# psoc6a2m register map
Vendor: Cypress Semiconductor; Series: psoc6a2m; File version: 1.0
CPU: CM4 r0p1, little endian, MPU, FPU, VTOR, 3 interrupt priority bits
Registers are 32-bit, read-write, reset 0x0 unless marked. A register's access mark holds for its fields unless they carry their own. Offsets are from the block's base; [hi:lo] are bit positions; 'fields as' and 'values as' point back to an identical list; <NAME> marks a mode.

## CSD0 — Capsense Controller
Base 0x40360000
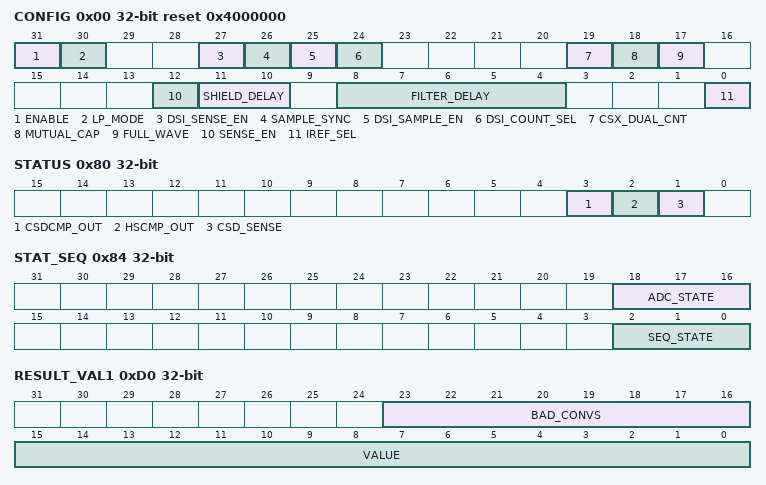
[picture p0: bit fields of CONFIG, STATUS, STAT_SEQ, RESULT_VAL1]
0x00 CONFIG reset 0x4000000 — Configuration and Control
  [31] ENABLE
  [30] LP_MODE
  [27] DSI_SENSE_EN — DSI_SENSE_EN = 1-> sensor clock is driven directly by DSI DSI_SENSE_EN = 0-> sensor clock is driven by PRS/divide-by-2/DIRECT_CLOCK
  [26] SAMPLE_SYNC
  [25] DSI_SAMPLE_EN — DSI_SAMPLE_EN = 1 -> COUNTER will count the samples generated by DSI DSI_SAMPLE_EN = 0 -> COUNTER will count the samples generated by CSD modulator
  [24] DSI_COUNT_SEL
    0=CSD_RESULT (N/A); 1=ADC_RESULT (N/A)
  [19] CSX_DUAL_CNT
    0=ONE (N/A); 1=TWO (N/A)
  [18] MUTUAL_CAP
    0=SELFCAP (Self-cap mode); 1=MUTUALCAP (Mutual-cap mode)
  [17] FULL_WAVE
    0=HALFWAVE (Half Wave mode); 1=FULLWAVE (Full Wave mode)
  [12] SENSE_EN — Enables the sensor and shield clocks, CSD modulator output and turns on the IDAC compensation current as selected by CSD_IDAC.
  [11:10] SHIELD_DELAY — Configures the delay between shield clock and sensor clock
    0=OFF (Delay line is off; sensor clock = shield clock); 1=D5NS (shield clock is delayed by 5ns delay w.r.t sensor clock); 2=D10NS (shield clock is delayed by 10ns delay w.r.t sensor clock); 3=D20NS (shield clock is delayed by 20ns delay w.r.t sensor clock)
  [8:4] FILTER_DELAY — Enables the digital filtering on the CSD comparator
  [0] IREF_SEL
    0=IREF_SRSS (N/A); 1=IREF_PASS (N/A)
0x04 SPARE — Spare MMIO
  [3:0] SPARE
0x80 STATUS ro
  [3] CSDCMP_OUT — Only for Debug/test purpose the output status of CSD modulator can be read by CPU
  [2] HSCMP_OUT — Only for Debug/test purpose the output status of CSD comparator can be read by CPU
    0=C_LT_VREF (N/A); 1=C_GT_VREF (N/A)
  [1] CSD_SENSE — Only for Debug/test purpose this internal signal (sensor clock) status can be read by CPU
0x84 STAT_SEQ ro — Current Sequencer status
  [18:16] ADC_STATE — ADC sequencer state (only relevant after SEQ_STATE has reached SAMPLE_NORM and ADC sequencer has started)
  [2:0] SEQ_STATE — CSD sequencer state
0x88 STAT_CNTS ro — Current status counts
  [15:0] NUM_CONV — Current number of conversions remaining when in Sample_* states (note that in AutoZero* states the same down counter is reused to count the cycles)
0x8C STAT_HCNT ro — Current count of the HSCMP counter
  [15:0] CNT — Current value of HSCMP counter
0xD0 RESULT_VAL1 ro — Result CSD/CSX accumulation counter value 1
  [23:16] BAD_CONVS — Number of 'bad' conversion for which the CSD comparator did not trigger within the normal time window, either because Vref was not crossed at all, or if the Vref was already crossed before the window started. This counter is reset when the sequencer is started and will saturate at 255 when more than 255 conversions are bad.
  [15:0] VALUE — Accumulated counter value for this result. In case of Mutual cap with two counters (CSX = config.mutual_cap & config.csx_dual_cnt) this counter counts when csd_sense is high.
0xD4 RESULT_VAL2 ro — Result CSX accumulation counter value 2
  [15:0] VALUE — Only used in case of Mutual cap with two counters (CSX = config.mutual_cap & config.csx_dual_cnt), this counter counts when csd_sense is low.
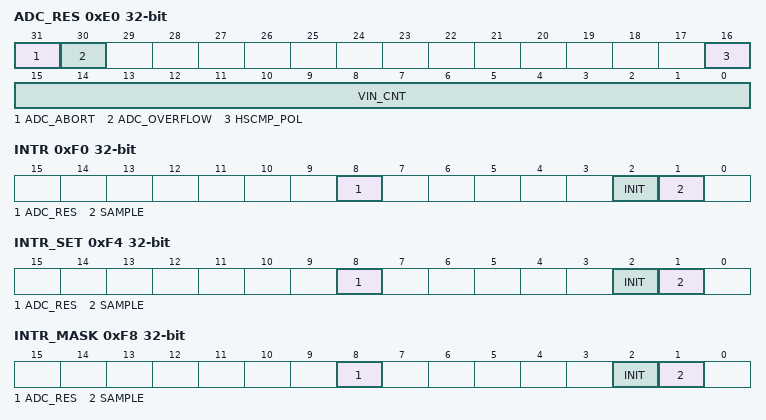
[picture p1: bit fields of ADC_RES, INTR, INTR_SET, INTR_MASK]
0xE0 ADC_RES ro — ADC measurement
  [31] ADC_ABORT — This flag is set when the ADC sequencer was aborted before tripping HSCMP.
  [30] ADC_OVERFLOW — This flag is set when the ADC counter overflows. This is an indication to the firmware that the IDACB current level is too low.
  [16] HSCMP_POL — Polarity used for IDACB for this last ADC result, 0= source, 1= sink
  [15:0] VIN_CNT — Count to source/sink Cref1 + Cref2 from Vin to Vrefhi.
0xF0 INTR — CSD Interrupt Request Register
  [8] ADC_RES — ADC Result ready
  [2] INIT — Coarse initialization complete or Sample initialization complete (the latter is typically ignored)
  [1] SAMPLE — A normal sample is complete
0xF4 INTR_SET — CSD Interrupt set register
  [8] ADC_RES — Write with '1' to set corresponding bit in interrupt request register.
  [2] INIT — Write with '1' to set corresponding bit in interrupt request register.
  [1] SAMPLE — Write with '1' to set corresponding bit in interrupt request register.
0xF8 INTR_MASK — CSD Interrupt mask register
  [8] ADC_RES — Mask bit for corresponding bit in interrupt request register.
  [2] INIT — Mask bit for corresponding bit in interrupt request register.
  [1] SAMPLE — Mask bit for corresponding bit in interrupt request register.
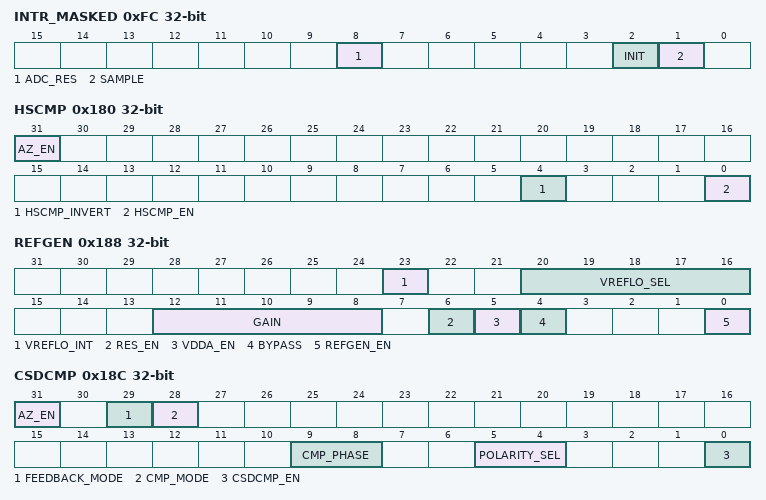
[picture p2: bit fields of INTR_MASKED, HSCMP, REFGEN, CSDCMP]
0xFC INTR_MASKED ro — CSD Interrupt masked register
  [8] ADC_RES — Logical and of corresponding request and mask bits.
  [2] INIT — Logical and of corresponding request and mask bits.
  [1] SAMPLE — Logical and of corresponding request and mask bits.
0x180 HSCMP — High Speed Comparator configuration
  [31] AZ_EN — Auto-Zero enable, allow the Sequencer to Auto-Zero this component
  [4] HSCMP_INVERT — Invert the HSCMP output before it is used to control switches and the CSD sequencer. This bit does not affect the ADC sequencer or the STATUS.HSCMP_OUT
  [0] HSCMP_EN — High Speed Comparator enable
    0=OFF (Disable comparator, output is zero); 1=ON (On, regular operation. Note that CONFIG.LP_MODE determines the power mode level)
0x184 AMBUF — Reference Generator configuration
  [1:0] PWR_MODE — Amux buffer power level
    0=OFF (Disable buffer); 1=NORM (On, normal or low power level depending on CONFIG.LP_MODE.); 2=HI (On, high or low power level depending on CONFIG.LP_MODE.)
0x188 REFGEN — Reference Generator configuration
  [23] VREFLO_INT — Ouput the resistor string tap either to Vreflo (0) or Vreflo_int (1).
  [20:16] VREFLO_SEL — Select resistor string tap for Vreflo/Vreflo_int, 0= minimum vout, 31= maximum vout = vrefhi (only works if the resistor string is enabled; RES_EN=1)
  [12:8] GAIN — Select resistor string tap for feedback, 0= minimum vout, 31= maximum vout = vrefhi -> gain=1 (only works if the resistor string is enabled; RES_EN=1)
  [6] RES_EN — Resistor string enable; 0= open switch on top of the resistor string (Vreflo=Vssa)
  [5] VDDA_EN — Close Vdda switch to top of resistor string (or Vrefhi?)
  [4] BYPASS — Bypass selected input reference unbuffered to Vrefhi
  [0] REFGEN_EN — Reference Generator Enable
    0=OFF (Disable Reference Generator); 1=ON (On, regular operation. Note that CONFIG.LP_MODE determines the power mode level)
0x18C CSDCMP — CSD Comparator configuration
  [31] AZ_EN — Auto-Zero enable, allow the Sequencer to Auto-Zero this component
  [29] FEEDBACK_MODE — This bit controls whether the output directly from the comparator (csdcmp_out) or the flopped version (csdcmp_out_ff) is used. For CSD operation, the selected signal controls the IDAC(s), in GP mode the signal goes out on dsi_sample_out.
    0=FLOP (Use feedback from sampling flip-flop (used in most modes).); 1=COMP (Use feedback from comparator directly (used in single Cmod mutual cap sensing only))
  [28] CMP_MODE — Select which signal to output on dsi_sample_out.
    0=CSD (CSD mode: output the filtered sample signal on dsi_sample_out); 1=GP (General Purpose mode: output the unfiltered sample unfiltered comparator output, either asynchronous or flopped.)
  [9:8] CMP_PHASE — Select in what phase(s) the comparator is active, typically set to match the BAL_MODE of the used IDAC. Note, this also determines when a bad conversion is detected, namely at the beginning and end of the comparator active phase (also taking into account FILTER_DELAY and non-overlap).
    0=FULL (Comparator is active from start of Phi2 and kept active into Phi1. Intended usage: legacy CSD for balancing over a full csd_sense period (non-overlap should be turned off)); 1=PHI1 (Comparator is active during Phi1 only. Currently no known use-case.); 2=PHI2 (Comparator is active during Phi2 only. Intended usage: CSD Low EMI.); 3=PHI1_2 (Comparator is activated at the start of both Phi1 and Phi2 (non-overlap should be enabled). Intended usage: CSX, or Full-Wave.)
  [5:4] POLARITY_SEL — Select which IDAC polarity to use to detect CSDCMP triggering
    0=IDACA_POL (Use idaca_pol (firmware setting with CSX and optionally DSI mixed in) to determine the direction, this is the most common use-case, used for normal CSD and normal CSX); 1=IDACB_POL (Use idacb_pol (firmware setting with optional DSI mixed in) to determine the direction, this is only used for normal CSD if IDACB is used i.s.o. IDACA (not common)); 2=DUAL_POL (Use the expression (csd_sense ? idaca_pol : idacb_pol) to determine the direction, this is only useful for the CSX with DUAL_IDAC use-case)
  [0] CSDCMP_EN — CSD Comparator Enable
    values as HSCMP.HSCMP_EN
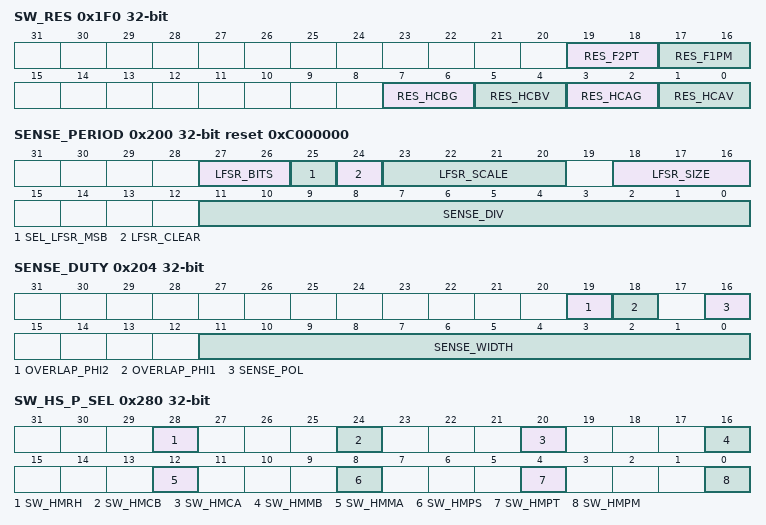
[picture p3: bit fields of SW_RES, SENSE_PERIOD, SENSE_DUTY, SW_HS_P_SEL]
0x1F0 SW_RES — Switch Resistance configuration
  [19:18] RES_F2PT — Select resistance for the corresponding switch
  [17:16] RES_F1PM — Select resistance for the corresponding switch
    0=LOW; 1=MED (Medium); 2=HIGH; 3=RSVD (N/A)
  [7:6] RES_HCBG — Select resistance or low EMI for the corresponding switch
  [5:4] RES_HCBV — Select resistance or low EMI for the corresponding switch
  [3:2] RES_HCAG — Select resistance or low EMI for the corresponding switch
  [1:0] RES_HCAV — Select resistance or low EMI (slow ramp) for the HCAV switch
    0=LOW; 1=MED (Medium); 2=HIGH; 3=LOWEMI (Low EMI (slow ramp: 3 switches closed by fixed delay line))
0x200 SENSE_PERIOD reset 0xC000000 — Sense clock period
  [27:26] LFSR_BITS — Selects the number of LSB bits to use from the LSFR to provide the clock dithering variation on the base period. Caveat make sure that SENSE_DIV > the maximum absolute range (e.g. for 4B SENSE_DIV > 8), otherwise results are undefined.
    0=2B (use 2 bits: range = [-2,1]); 1=3B (use 3 bits: range = [-4,3]); 2=4B (use 4 bits: range = [-8,7]); 3=5B (use 5 bits: range = [-16,15] (default))
  [25] SEL_LFSR_MSB — Use the MSB of configured LSFR size as csd_sense signal. Intended to be used only with bit 8 or 12-bit LFSR size for CSDv1 backward compatibility (PRS). When this bit is set then clock divider dithering is disabled and SENSE_WIDTH is disabled.
  [24] LFSR_CLEAR — When set, forces the LFSR to it's initial state (all ones). This bit is automatically cleared by hardware after the LFSR is cleared, which is at the next clk_csd positive edge. This bit should be set whenever this register is written and the LFSR is used. Note that the LFSR will also get reset to all ones during the AutoZero_1/2 states.
  [23:20] LFSR_SCALE — Shift the LFSR output left by LSFR_SCALE bits before adding to SENSE_DIV. This dithering is disabled when SEL_LSFR_MSB is set. The clock divider to be used = (SENSE_DIV+1) + (SEL_LSFR_MSB ? 0 : (LFSR_OUT<<LFSR_SCALE)). Note that the clock divider including the dithering term must fit in 12 bits, otherwise the result is undefined.
  [18:16] LFSR_SIZE — Selects the length of the LFSR which determines the LFSR repeat period. LFSR_BITS LSB of the LFSR are used for the clock dithering variation on the base period (was PRS in CSDv1). Whenever the LFSR is used (non zero value in this field) the LFSR_CLEAR bit should also be set.
    0=OFF (Don't use clock dithering (=spreadspectrum) (LFSR output value is zero)); 1=6B (6-bit LFSR (G(x)=X^6 +X^4+X^3+ X+1, period= 63)); 2=7B (7-bit LFSR (G(x)=X^7 +X^4+X^3+X^2+1, period= 127)); 3=9B (9-bit LFSR (G(x)=X^9 +X^4+X^3+ X+1, period= 511)); 4=10B (10-bit LFSR (G(x)=X^10+X^4+X^3+ X+1, period= 1023)); 5=8B (8-bit LFSR (G(x)=X^8+X^4+X^3+X^2+1, period= 255)); 6=12B (12-bit LFSR (G(x)=X^12+X^7+X^4+X^3+1, period= 4095))
  [11:0] SENSE_DIV — The length-1 of the Sense modulation 'clock' period in clk_csd cycles. For regular CSD one sense clock cycle = one conversion (=phi1+phi2) . Note this is the base divider, clock dithering may change the actual period length. Note that SENSE_DIV must be at least 1 and additionally also allow for one clk_hf of non overlap (if OVERLAP_HI1/2 is set) on both phases, i.e. if clk_csd=clk_hf then SENSE_DIV must be >=3. In addition the FILTER_DELAY needs to be added to the minimum allowed SENSE_DIV value.
0x204 SENSE_DUTY — Sense clock duty cycle
  [19] OVERLAP_PHI2 — Same as OVERLAP_PHI1 but for Phi2 (csd_sense=1).
  [18] OVERLAP_PHI1 — NonOverlap or not for Phi1 (csd_sense=0). 0 = Non-overlap for Phi1, the Phi1 signal is csd_sense inverted except that the signal goes low 1 clk_sample before csd_sense goes high. Intended usage: new low EMI CSD/CSX with static GPIO. 1 = 'Overlap' (= not non-overlap) for Phi1, the Phi1 signal is csd_sense inverted. Intended usage: legacy CSD with GPIO switching, the GPIO internal circuit ensures that the switches are non-overlapping.
  [16] SENSE_POL — Polarity of the sense clock 0 = start with low phase (typical for regular negative transfer CSD) 1 = start with high phase
  [11:0] SENSE_WIDTH — Defines the length of the first phase of the sense clock in clk_csd cycles. A value of 0 disables this feature and the duty cycle of csd_sense will be 50 percent, which is equal to SENSE_WIDTH = (SENSE_DIV+1)/2, or when clock dithering is used that becomes [(SENSE_DIV+1) + (LFSR_OUT << LSFR_SCALE)]/2. At all times it must be assured that the phases are at least 2 clk_csd cycles (1 for non overlap, if used), if this rule is violated the result is undefined. Note that this feature is not available when SEL_LFSR_MSB (PRS) is selected.
0x280 SW_HS_P_SEL — HSCMP Pos input switch Waveform selection
  [28] SW_HMRH — Set corresponding switch
  [24] SW_HMCB — Set corresponding switch
  [20] SW_HMCA — Set corresponding switch
  [16] SW_HMMB — Set corresponding switch
  [12] SW_HMMA — Set corresponding switch
  [8] SW_HMPS — Set corresponding switch
  [4] SW_HMPT — Set corresponding switch
  [0] SW_HMPM — Set HMPM switch 0: static open 1: static closed
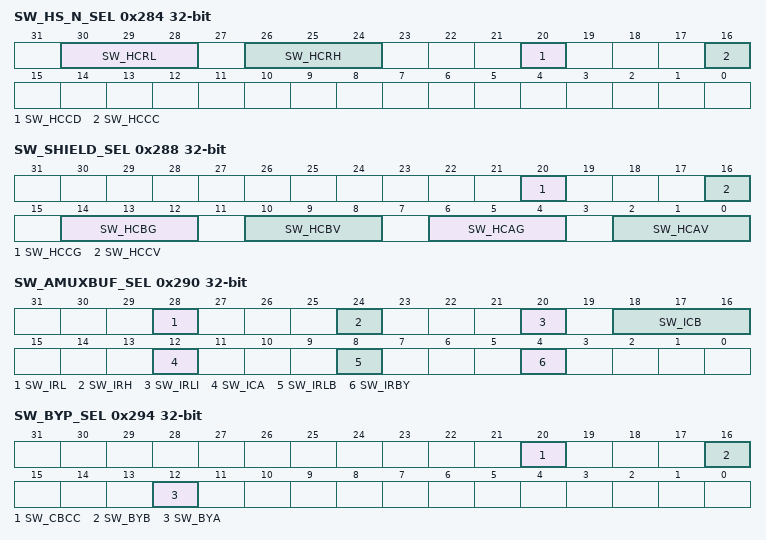
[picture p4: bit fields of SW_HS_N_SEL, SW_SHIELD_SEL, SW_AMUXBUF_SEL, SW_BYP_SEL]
0x284 SW_HS_N_SEL — HSCMP Neg input switch Waveform selection
  [30:28] SW_HCRL — Select waveform for corresponding switch
  [26:24] SW_HCRH — Select waveform for corresponding switch
  [20] SW_HCCD — Set corresponding switch
  [16] SW_HCCC — Set corresponding switch
0x288 SW_SHIELD_SEL — Shielding switches Waveform selection
  [20] SW_HCCG — Set corresponding switch If the ADC is enabled then this switch is directly controlled by the ADC sequencer.
  [16] SW_HCCV — Set corresponding switch
  [14:12] SW_HCBG — Select waveform for corresponding switch, using csd_shield as base
  [10:8] SW_HCBV
  [6:4] SW_HCAG — Select waveform for corresponding switch
  [2:0] SW_HCAV
0x290 SW_AMUXBUF_SEL — Amuxbuffer switches Waveform selection
  [28] SW_IRL — Set corresponding switch
  [24] SW_IRH — Set corresponding switch
  [20] SW_IRLI — Set corresponding switch
  [18:16] SW_ICB — Select waveform for corresponding switch
  [12] SW_ICA — Set corresponding switch
  [8] SW_IRLB — Set corresponding switch
  [4] SW_IRBY — Set corresponding switch
0x294 SW_BYP_SEL — AMUXBUS bypass switches Waveform selection
  [20] SW_CBCC — Set corresponding switch If the ADC is enabled then this switch is directly controlled by the ADC sequencer.
  [16] SW_BYB — Set corresponding switch
  [12] SW_BYA — Set corresponding switch
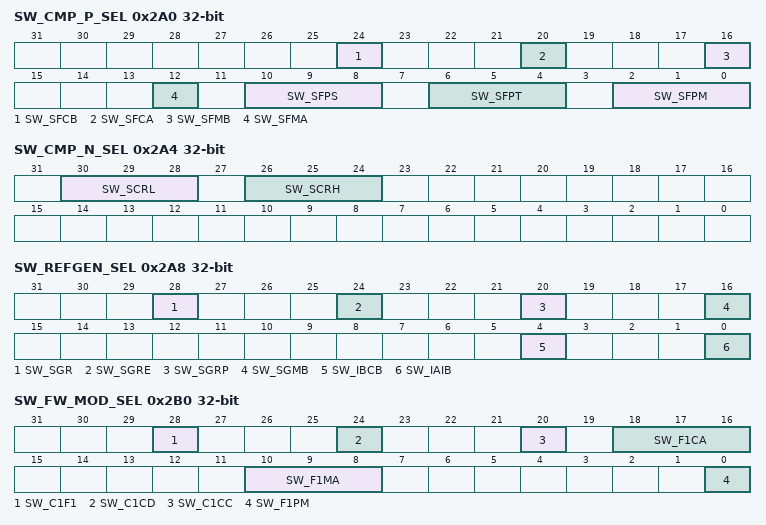
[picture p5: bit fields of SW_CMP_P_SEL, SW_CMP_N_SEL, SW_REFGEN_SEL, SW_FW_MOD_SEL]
0x2A0 SW_CMP_P_SEL — CSDCMP Pos Switch Waveform selection
  [24] SW_SFCB — Set corresponding switch
  [20] SW_SFCA — Set corresponding switch
  [16] SW_SFMB — Set corresponding switch
  [12] SW_SFMA — Set corresponding switch
  [10:8] SW_SFPS — Select waveform for corresponding switch
  [6:4] SW_SFPT — Select waveform for corresponding switch
  [2:0] SW_SFPM — Select waveform for corresponding switch
0x2A4 SW_CMP_N_SEL — CSDCMP Neg Switch Waveform selection
  [30:28] SW_SCRL — Select waveform for corresponding switch
  [26:24] SW_SCRH — Select waveform for corresponding switch
0x2A8 SW_REFGEN_SEL — Reference Generator Switch Waveform selection
  [28] SW_SGR — Set corresponding switch
  [24] SW_SGRE — Set corresponding switch
  [20] SW_SGRP — Set corresponding switch
  [16] SW_SGMB — Set corresponding switch
  [4] SW_IBCB — Set corresponding switch
  [0] SW_IAIB — Set corresponding switch
0x2B0 SW_FW_MOD_SEL — Full Wave Cmod Switch Waveform selection
  [28] SW_C1F1 — Set corresponding switch
  [24] SW_C1CD — Set corresponding switch
  [20] SW_C1CC — Set corresponding switch
  [18:16] SW_F1CA — Select waveform for corresponding switch
  [10:8] SW_F1MA — Select waveform for corresponding switch
  [0] SW_F1PM — Set corresponding switch
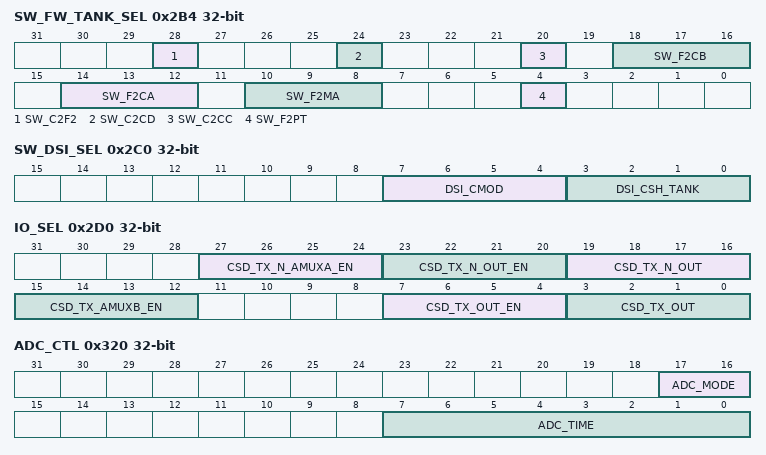
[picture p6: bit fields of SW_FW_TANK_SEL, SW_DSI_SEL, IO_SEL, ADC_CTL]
0x2B4 SW_FW_TANK_SEL — Full Wave Csh_tank Switch Waveform selection
  [28] SW_C2F2 — Set corresponding switch
  [24] SW_C2CD — Set corresponding switch
  [20] SW_C2CC — Set corresponding switch
  [18:16] SW_F2CB — Select waveform for corresponding switch
  [14:12] SW_F2CA — Select waveform for corresponding switch
  [10:8] SW_F2MA — Select waveform for corresponding switch
  [4] SW_F2PT — Set corresponding switch
0x2C0 SW_DSI_SEL — DSI output switch control Waveform selection
  [7:4] DSI_CMOD — Select waveform for dsi_cmod output signal
  [3:0] DSI_CSH_TANK — Select waveform for dsi_csh_tank output signal 0: static open 1: static closed 2: phi1 3: phi2 4: phi1 & HSCMP 5: phi2 & HSCMP 6: HSCMP // ignores phi1/2 7: !sense // = phi1 but ignores OVERLAP_PHI1 8: phi1_delay // phi1 delayed with shield delay 9: phi2_delay // phi2 delayed with shield delay 10: !phi1 11: !phi2 12: !(phi1 & HSCMP) 13: !(phi2 & HSCMP) 14: !HSCMP // ignores phi1/2 15: sense // = phi2 but ignores OVERLAP_PHI2
0x2D0 IO_SEL — IO output control Waveform selection
  [27:24] CSD_TX_N_AMUXA_EN — Select waveform for csd_tx_n_amuxa_en output signal
  [23:20] CSD_TX_N_OUT_EN — Select waveform for csd_tx_n_out_en output signal
  [19:16] CSD_TX_N_OUT — Select waveform for csd_tx_n_out output signal
  [15:12] CSD_TX_AMUXB_EN — Select waveform for csd_tx_amuxb_en output signal
  [7:4] CSD_TX_OUT_EN — Select waveform for csd_tx_out_en output signal
  [3:0] CSD_TX_OUT — Select waveform for csd_tx_out output signal
0x300 SEQ_TIME — Sequencer Timing
  [7:0] AZ_TIME — Define Auto-Zero time in csd_sense cycles -1.
0x310 SEQ_INIT_CNT — Sequencer Initial conversion and sample counts
  [15:0] CONV_CNT — Number of conversion per Initialization sample, if set to 0 the Sample_init state will be skipped.
0x314 SEQ_NORM_CNT — Sequencer Normal conversion and sample counts
  [15:0] CONV_CNT — Number of conversion per sample, if set to 0 the Sample_norm state will be skipped. Sample window size = SEQ_NORM_CNT.CONV_CNT * (SENSE_PERIOD.SENSE_DIV+1). Note for CSDv1 Sample window size = PERIOD
0x320 ADC_CTL — ADC Control
  [17:16] ADC_MODE — Enable ADC measurement. When enabled the ADC sequencer will be started when the main sequencer goes to the SAMPLE_NORM state
    0=OFF (No ADC measurement); 1=VREF_CNT (Count time A to bring Cref1 + Cref2 up from Vssa to Vrefhi with IDACB); 2=VREF_BY2_CNT (Count time B to bring Cref1 + Cref2 back up to Vrefhi with IDACB (after bringing them down for time A/2 cycles with IDACB sinking)); 3=VIN_CNT (Determine HSCMP polarity and count time C to source/sink Cref1 + Cref2 from Vin to Vrefhi.)
  [7:0] ADC_TIME — ADC timing -1 in csd_sense clock cycles (actual time is ADC_TIME+1 cycles), either used to discharge Cref1&2, or as the aperture to capture the input voltage on Cref1&2
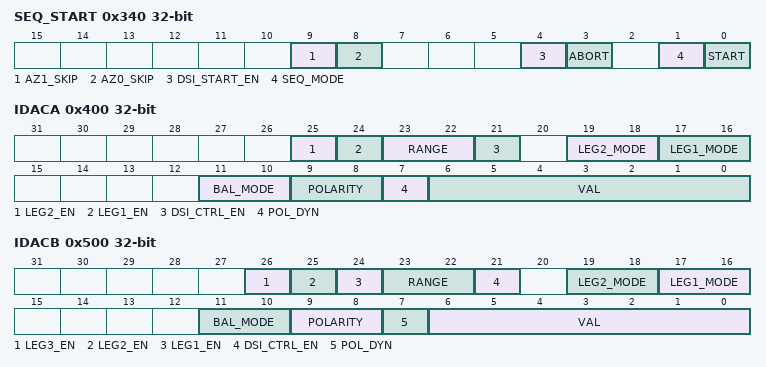
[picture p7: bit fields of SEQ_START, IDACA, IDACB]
0x340 SEQ_START — Sequencer start
  [9] AZ1_SKIP — When set the AutoZero_1 state will be skipped
  [8] AZ0_SKIP — When set the AutoZero_0 state will be skipped
  [4] DSI_START_EN — When this bit is set a positive edge on dsi_start will start the CSD sequencer and if enabled also the ADC sequencer.
  [3] ABORT — When a 1 is written the CSD and ADC sequencers will be aborted (if they are running) and the START bit will be cleared. This bit always read as 0.
  [1] SEQ_MODE — 0 = regular CSD scan + optional ADC 1 = coarse initialization, the Sequencer will go to the INIT_COARSE state.
  [0] START — Start the CSD sequencer. The sequencer will clear this bit when it is done. Depending on the mode the sequencer is done when a sample has been accumulated, when the high speed comparator trips or if the sequencer is aborted. When the ADC is enabled the ADC sequencer will start when the CSD sequencer reaches the Sample_norm state (only with the regular CSD scan mode).
0x400 IDACA — IDACA Configuration
  [25] LEG2_EN
  [24] LEG1_EN
  [23:22] RANGE
    0=IDAC_LO (N/A); 1=IDAC_MED (N/A); 2=IDAC_HI (N/A)
  [21] DSI_CTRL_EN
  [19:18] LEG2_MODE
    0=GP_STATIC (N/A); 1=GP (N/A); 2=CSD_STATIC (N/A); 3=CSD (N/A)
  [17:16] LEG1_MODE
    values as LEG2_MODE
  [11:10] BAL_MODE
    0=FULL (N/A); 1=PHI1 (N/A); 2=PHI2 (N/A); 3=PHI1_2 (N/A)
  [9:8] POLARITY
    0=VSSA_SRC (Normal: sensor switching between Vssio and Cmod. For non-CSD application, IDAC1 will source current.); 1=VDDA_SNK (Inverted: sensor switch between Vddio and Cmod. For non-CSD application, IDAC1 will sink current.); 2=SENSE (N/A); 3=SENSE_INV (N/A)
  [7] POL_DYN
    0=STATIC (N/A); 1=DYNAMIC (N/A)
  [6:0] VAL
0x500 IDACB — IDACB Configuration
  [26] LEG3_EN
  [25] LEG2_EN
  [24] LEG1_EN
  [23:22] RANGE
    0=IDAC_LO (N/A); 1=IDAC_MED (N/A); 2=IDAC_HI (N/A)
  [21] DSI_CTRL_EN
  [19:18] LEG2_MODE
    values as IDACA.LEG2_MODE
  [17:16] LEG1_MODE
    values as IDACA.LEG2_MODE
  [11:10] BAL_MODE
    0=FULL (N/A); 1=PHI1 (N/A); 2=PHI2 (N/A); 3=PHI1_2 (N/A)
  [9:8] POLARITY
    values as IDACA.POLARITY
  [7] POL_DYN
    0=STATIC (N/A); 1=DYNAMIC (N/A)
  [6:0] VAL
